VERSION ""

NS_ :

BS_:

BU_: RadarObj

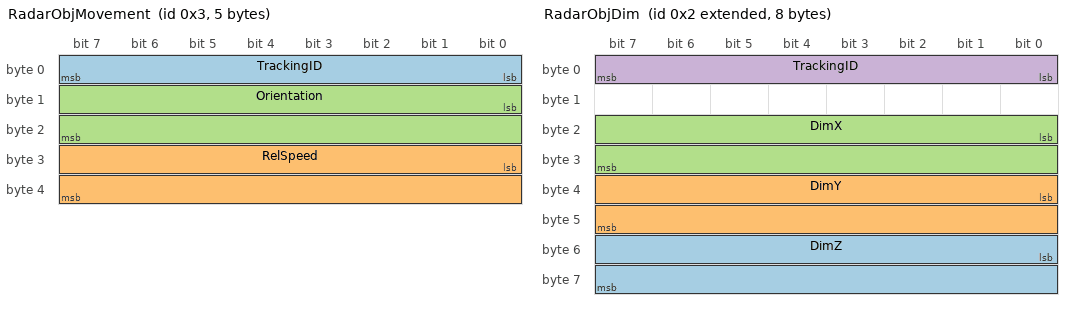
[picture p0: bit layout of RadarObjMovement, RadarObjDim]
BO_ 3 RadarObjMovement: 5 Vector__XXX
 SG_ TrackingID : 0|8@1+ (1,0) [0|255] "" Vector__XXX
 SG_ RelSpeed : 24|16@1- (0.1,0) [-3276.8|3276.7] "m/s" Vector__XXX
 SG_ Orientation : 8|16@1- (0.1,0) [-3276.8|3276.7] "°" Vector__XXX

BO_ 2147483650 RadarObjDim: 8 RadarObj
 SG_ DimZ : 48|16@1- (0.1,0) [-3276.8|3276.7] "m" Vector__XXX
 SG_ DimY : 32|16@1- (0.1,0) [-3276.8|3276.7] "m" Vector__XXX
 SG_ DimX : 16|16@1- (0.1,0) [-3276.8|3276.7] "m" Vector__XXX
 SG_ TrackingID : 0|8@1+ (1,0) [0|255] "" Vector__XXX

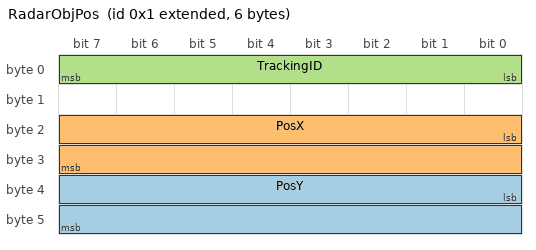
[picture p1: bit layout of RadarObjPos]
BO_ 2147483649 RadarObjPos: 6 RadarObj
 SG_ PosY : 32|16@1- (0.1,0) [-3276.8|3276.7] "m" Vector__XXX
 SG_ PosX : 16|16@1- (0.1,0) [-3276.8|3276.7] "m" Vector__XXX
 SG_ TrackingID : 0|8@1+ (1,0) [0|255] "" Vector__XXX

BA_DEF_ BO_  "CANFD_BRS" ENUM  "0","1";
BA_DEF_  "DBName" STRING ;
BA_DEF_  "BusType" STRING ;
BA_DEF_ BO_  "VFrameFormat" ENUM  "StandardCAN","ExtendedCAN","reserved","reserved","reserved","reserved","reserved","reserved","reserved","reserved","reserved","reserved","reserved","reserved","StandardCAN_FD","ExtendedCAN_FD";
BA_DEF_DEF_  "CANFD_BRS" "1";
BA_DEF_DEF_  "DBName" "";
BA_DEF_DEF_  "BusType" "";
BA_DEF_DEF_  "VFrameFormat" "StandardCAN";
BA_ "BusType" "CAN FD";
BA_ "DBName" "RadarObjectsCAN";
BA_ "VFrameFormat" BO_ 3 14;
BA_ "VFrameFormat" BO_ 2147483650 15;
BA_ "VFrameFormat" BO_ 2147483649 15;
